# PIC32CX1012BZ25032 register map
Vendor: Microchip Technology; Series: BZ25; File version: 0
Microchip PIC32CX1012BZ25032 Microcontroller
CPU: CM4 r0p1, little endian, MPU, FPU, 3 interrupt priority bits
Registers are 32-bit, read-write, reset 0x0 unless marked. A register's access mark holds for its fields unless they carry their own. Offsets are from the block's base; lines under a group give offsets from that group; [hi:lo] are bit positions; {n}, {i} and the like mark numbered series; 'fields as' and 'values as' point back to an identical list; <NAME> marks a mode.

## Memory map
0x40000000 PAC size 0x40 — Peripheral Access Controller
0x40000400 FREQM size 0x14 — Frequency Meter
0x40000800 EIC size 0x3C — External Interrupt Controller
0x40000C00 SERCOM0 size 0x31 — Serial Communication Interface
0x40001000 SERCOM1 size 0x31
0x40001400 TC0 size 0x38 — Basic Timer Counter
0x40001800 TC1 size 0x38
0x40001C00 TC2 size 0x38
0x40002000 TC3 size 0x38
0x40002400 TCC0 size 0x88 — Timer Counter Control
0x40002800 TCC1 size 0x88
0x40002C00 TCC2 size 0x88
0x41000000 DSU size 0x2000 — Device Service Unit
0x41002000 CMCC size 0x38 — Cortex M Cache Controller
0x41004000 DMAC size 0x1A0 — Direct Memory Access Controller
0x41006000 EVSYS size 0x268 — Event System Interface
0x41008000 RAMECC size 0x10
0x41010000 ZIGBEE — ZIGBEE Radio Registers
0x41011000 ARB size 0x1C — Radio Arbiter
0x41012000 BLE size 0x4BC
0x41014000 BTZBSYS size 0x28 — BT ZB Subsystem
0x42000000 QSPI size 0x48 — Quad SPI interface
0x42000400 AES size 0x88 — Advanced Encryption Standard
0x42001800 CCL size 0x10 — Configurable Custom Logic
0x42002400 HMATRIX size 0xB0 — HSB Matrix
0x42002800 TRNG size 0x24 — True Random Generator
0x42002C00 ICM size 0x58 — Integrity Check Monitor
0x42010000 RTC size 0xA0 — Real-Time Counter
0x42011000 DSCON size 0x14
0x44000000 CFG size 0x204
0x44000500 WDT size 0x10 — Watch Dog Timer
0x44000600 NVM size 0x110 — flash controller
0x44000800 PFW size 0x174 — flash wrapper
0x44000A00 CRU size 0x194
0x44000A00 RCON size 0x60
0x44000E00 DMT size 0x80 — Dead Man Timer
0x44001000 PPS size 0x2DC
0x44001400 ADCHS size 0xAB4 — 12-bit Analog to Digital Converter
0x44002200 GPIOA size 0xE0 — GPIO
0x44002300 GPIOB size 0xE0
0x44012400 PCHE size 0x34 — this is the PCHE
0x44013E00 PMU size 0x60 — PMU SPI controller
0xE0000000 ITM size 0xF00 — Instrumentation Trace Macrocell
0xE0001000 DWT size 0x5C — Data Watchpoint and Trace Register
0xE000E000 SystemControl size 0xD8C — System Control Registers
0xE000E010 SysTick size 0x10 — System timer
0xE000E100 NVIC size 0xE04 — Nested Vectored Interrupt Controller
0xE000ED90 MPU size 0x2C — Memory Protection Unit
0xE000EDF0 CoreDebug size 0x10
0xE000EF30 FPU size 0x18 — Floating Point Unit
0xE0040000 TPI size 0xFD0 — Trace Port Interface Register
0xE0041000 ETM size 0x1000 — Embedded Trace Macrocell

## Interrupts
0 RTC
1 EIC
2 FREQM
3 FLASH_CONTROL (NVM)
4 CHANGE_NOTICE_A (GPIOA)
5 CHANGE_NOTICE_B (GPIOB)
6 DMAC_0_3 (DMAC)
7 DMAC_4_15 (DMAC)
8 EVSYS_0_3 (EVSYS)
9 EVSYS_4_11 (EVSYS)
10 PAC
11 RAMECC
12 SERCOM0
13 SERCOM1
16 TCC0
17 TCC1
18 TCC2
19 TC0
20 TC1
21 TC2
22 TC3
23 ADCHS
25 AES
26 TRNG
27 ICM
29 QSPI
30 ZB_INT0 (ZIGBEE)
31 BT_INT0 (BLE)
32 BT_INT1 (BLE)
33 ARBITER (ARB)
34 ADC_FAULT (ADCHS)
35 ADC_FCC (ADCHS)
36 ADC_BGVR_RDY (ADCHS)
37 CLKI_WAKEUP_NMI (BLE)
38 BT_LC (BLE)
39 BT_RC (BLE)

## AES — Advanced Encryption Standard
Base 0x42000400; register names take the prefix AES_
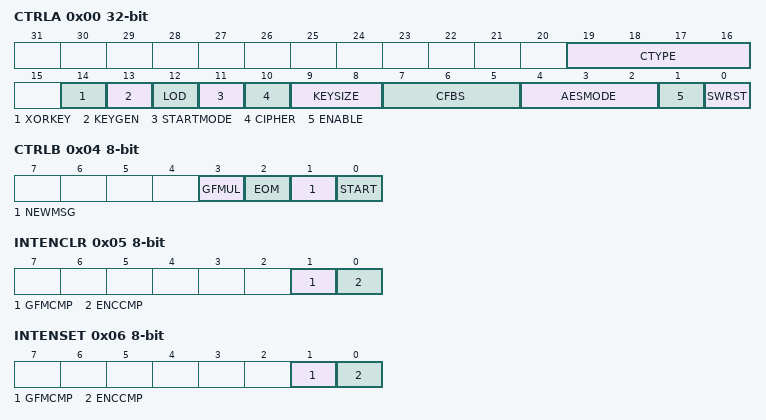
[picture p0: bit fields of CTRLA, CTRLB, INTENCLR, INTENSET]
0x00 CTRLA — Control A
  [19:16] CTYPE — Counter Measure Type
  [14] XORKEY — XOR Key Operation
    0=NONE (No effect); 1=XOR (The user keyword gets XORed with the previous keyword register content.)
  [13] KEYGEN — Last Key Generation
    0=NONE (No effect); 1=LAST (Start Computation of the last NK words of the expanded key)
  [12] LOD — Last Output Data Mode
    0=NONE (No effect); 1=LAST (Start encryption in Last Output Data mode)
  [11] STARTMODE — Start Mode Select
    0=MANUAL (Start Encryption / Decryption in Manual mode); 1=AUTO (Start Encryption / Decryption in Auto mode)
  [10] CIPHER — Cipher Mode
    0=DEC (Decryption); 1=ENC (Encryption)
  [9:8] KEYSIZE — Encryption Key Size
    0=128BIT (128-bit Key for Encryption / Decryption); 1=192BIT (192-bit Key for Encryption / Decryption); 2=256BIT (256-bit Key for Encryption / Decryption)
  [7:5] CFBS — Cipher Feedback Block Size
    0=128BIT (128-bit Input data block for Encryption/Decryption in Cipher Feedback mode); 1=64BIT (64-bit Input data block for Encryption/Decryption in Cipher Feedback mode); 2=32BIT (32-bit Input data block for Encryption/Decryption in Cipher Feedback mode); 3=16BIT (16-bit Input data block for Encryption/Decryption in Cipher Feedback mode); 4=8BIT (8-bit Input data block for Encryption/Decryption in Cipher Feedback mode)
  [4:2] AESMODE — AES Modes of operation
    0=ECB (Electronic code book mode); 1=CBC (Cipher block chaining mode); 2=OFB (Output feedback mode); 3=CFB (Cipher feedback mode); 4=COUNTER (Counter mode); 5=CCM (CCM mode); 6=GCM (Galois counter mode)
  [1] ENABLE
  [0] SWRST — Software Reset
0x04 CTRLB 8-bit — Control B
  [3] GFMUL — GF Multiplication
  [2] EOM — End of message
  [1] NEWMSG — New message
  [0] START — Start Encryption/Decryption
0x05 INTENCLR 8-bit — Interrupt Enable Clear
  [1] GFMCMP — GF Multiplication Complete Interrupt Enable
  [0] ENCCMP — Encryption Complete Interrupt Enable
0x06 INTENSET 8-bit — Interrupt Enable Set
  fields as INTENCLR
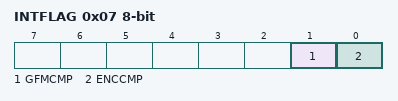
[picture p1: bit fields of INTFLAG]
0x07 INTFLAG 8-bit — Interrupt Flag Status
  [1] GFMCMP — GF Multiplication Complete
  [0] ENCCMP — Encryption Complete
0x08 DATABUFPTR 8-bit — Data buffer pointer
  [1:0] INDATAPTR — Input Data Pointer
0x09 DBGCTRL 8-bit — Debug control
  [0] DBGRUN — Debug Run
{0xC+4i} KEYWORD[{i}] (i=0..7) wo — Keyword n
0x38 INDATA
{0x3C+4i} INTVECTV[{i}] (i=0..3) wo — Initialisation Vector n
{0x5C+4i} HASHKEY[{i}] (i=0..3) — Hash key n
{0x6C+4i} GHASH[{i}] (i=0..3) — Galois Hash n
0x80 CIPLEN — Cipher Length
0x84 RANDSEED — Random Seed

## Notices in the file
Copyright (c) 2017 Microchip Technology Inc.
SPDX-License-Identifier: Apache-2.0
Licensed under the Apache License, Version 2.0 (the "License");
you may not use this file except in compliance with the License.
You may obtain a copy of the License at
http://www.apache.org/licenses/LICENSE-2.0
Unless required by applicable law or agreed to in writing, software
distributed under the License is distributed on an "AS IS" BASIS,
WITHOUT WARRANTIES OR CONDITIONS OF ANY KIND, either express or implied.
See the License for the specific language governing permissions and
limitations under the License.
